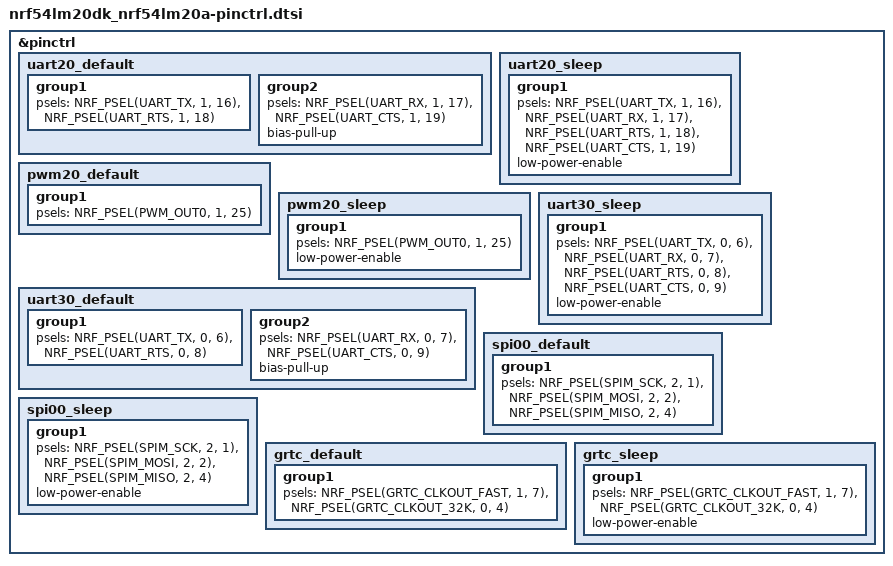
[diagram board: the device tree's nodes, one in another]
/*
 * Copyright (c) 2025 Nordic Semiconductor
 * SPDX-License-Identifier: Apache-2.0
 */

&pinctrl {
	/omit-if-no-ref/ uart20_default: uart20_default {
		group1 {
			psels = <NRF_PSEL(UART_TX, 1, 16)>,
				<NRF_PSEL(UART_RTS, 1, 18)>;
		};

		group2 {
			psels = <NRF_PSEL(UART_RX, 1, 17)>,
				<NRF_PSEL(UART_CTS, 1, 19)>;
			bias-pull-up;
		};
	};

	/omit-if-no-ref/ uart20_sleep: uart20_sleep {
		group1 {
			psels = <NRF_PSEL(UART_TX, 1, 16)>,
				<NRF_PSEL(UART_RX, 1, 17)>,
				<NRF_PSEL(UART_RTS, 1, 18)>,
				<NRF_PSEL(UART_CTS, 1, 19)>;
			low-power-enable;
		};
	};

	/omit-if-no-ref/ pwm20_default: pwm20_default {
		group1 {
			psels = <NRF_PSEL(PWM_OUT0, 1, 25)>;
		};
	};

	/omit-if-no-ref/ pwm20_sleep: pwm20_sleep {
		group1 {
			psels = <NRF_PSEL(PWM_OUT0, 1, 25)>;
			low-power-enable;
		};
	};

	/omit-if-no-ref/ uart30_default: uart30_default {
		group1 {
			psels = <NRF_PSEL(UART_TX, 0, 6)>,
				<NRF_PSEL(UART_RTS, 0, 8)>;
		};

		group2 {
			psels = <NRF_PSEL(UART_RX, 0, 7)>,
				<NRF_PSEL(UART_CTS, 0, 9)>;
			bias-pull-up;
		};
	};

	/omit-if-no-ref/ uart30_sleep: uart30_sleep {
		group1 {
			psels = <NRF_PSEL(UART_TX, 0, 6)>,
				<NRF_PSEL(UART_RX, 0, 7)>,
				<NRF_PSEL(UART_RTS, 0, 8)>,
				<NRF_PSEL(UART_CTS, 0, 9)>;
			low-power-enable;
		};
	};

	/omit-if-no-ref/ spi00_default: spi00_default {
		group1 {
			psels = <NRF_PSEL(SPIM_SCK, 2, 1)>,
				<NRF_PSEL(SPIM_MOSI, 2, 2)>,
				<NRF_PSEL(SPIM_MISO, 2, 4)>;
		};
	};

	/omit-if-no-ref/ spi00_sleep: spi00_sleep {
		group1 {
			psels = <NRF_PSEL(SPIM_SCK, 2, 1)>,
				<NRF_PSEL(SPIM_MOSI, 2, 2)>,
				<NRF_PSEL(SPIM_MISO, 2, 4)>;
			low-power-enable;
		};
	};

	/omit-if-no-ref/ grtc_default: grtc_default {
		group1 {
			psels = <NRF_PSEL(GRTC_CLKOUT_FAST, 1, 7)>,
				<NRF_PSEL(GRTC_CLKOUT_32K, 0, 4)>;
		};
	};

	/omit-if-no-ref/ grtc_sleep: grtc_sleep {
		group1 {
			psels = <NRF_PSEL(GRTC_CLKOUT_FAST, 1, 7)>,
				<NRF_PSEL(GRTC_CLKOUT_32K, 0, 4)>;
			low-power-enable;
		};
	};
};
